# STM32F413 register map
File version: 1.9
CPU: CM4 r0p1, little endian, MPU, FPU, 4 interrupt priority bits
Registers are 32-bit, read-write, reset 0x0 unless marked. A register's access mark holds for its fields unless they carry their own. Offsets are from the block's base; [hi:lo] are bit positions; <NAME> marks a mode.

## PWR — Power control
Base 0x40007000
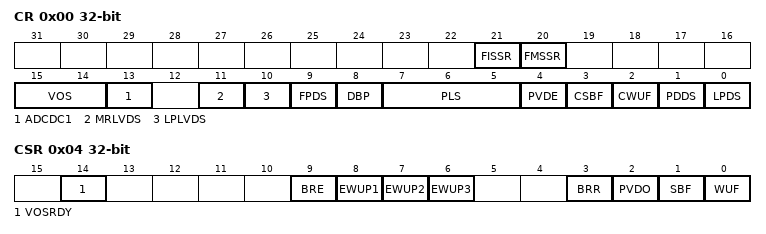
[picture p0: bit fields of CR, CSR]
0x00 CR — power control register
  [21] FISSR — Flash Interface Stop while System Run
    0=Run (Flash Interface clock run (Default value)); 1=Off (Flash Interface clock off)
  [20] FMSSR — Flash Memory Sleep System Run
    0=Standard (Flash standard mode (Default value)); 1=Forced (Flash forced to be in STOP or DeepPower Down mode (depending of FPDS value bit) by hardware)
  [15:14] VOS — Regulator voltage scaling output selection
    1=Scale 3 mode <= 64 MHz; 2=Scale 2 mode (reset value) <= 84 MHz; 3=Scale 1 mode <= 100 MHz
  [13] ADCDC1
  [11] MRLVDS — Main regulator Low Voltage in Deep Sleep
    0=Scale3 (Main regulator in Voltage scale 3 when the device is in Stop mode); 1=LowVoltage (Main regulator in Low Voltage and Flash memory in Deep Sleep mode when the device is in Stop mode)
  [10] LPLVDS — Low-power regulator Low Voltage in Deep Sleep
    0=On (Low-power regulator on if LPDS bit is set when the device is in Stop mode); 1=UnderDrive (Low-power regulator in Low Voltage and Flash memory in Deep Sleep mode if LPDS bit is set when device is in Stop mode)
  [9] FPDS — Flash power down in Stop mode
    0=Idle (Flash memory not in power-down when the device is in Stop mode); 1=PowerDown (Flash memory in power-down when the device is in Stop mode)
  [8] DBP — Disable backup domain write protection
    0=Protected (Access to RTC and RTC Backup registers and backup SRAM disabled); 1=Writable (Access to RTC and RTC Backup registers and backup SRAM enabled)
  [7:5] PLS — PVD level selection
  [4] PVDE — Power voltage detector enable
    0=Disabled (PVD disabled); 1=Enabled (PVD enabled)
  [3] CSBF — Clear standby flag
    on read: 0=Zero (This bit is always read as 0) | on write: 1=Clear the SBF Standby Flag
  [2] CWUF — Clear wakeup flag
    on read: 0=Zero (This bit is always read as 0) | on write: 1=Clear the WUPF Wakeup Flag **after 2 System clock cycles**
  [1] PDDS — Power down deepsleep
    0=Enter Stop mode when the CPU enters deepsleep. The regulator status depends on the LPDS bit; 1=Enter Standby mode when the CPU enters deepsleep
  [0] LPDS — Low-power deep sleep
    0=Main voltage regulator ON during Stop mode; 1=Low-power voltage regulator ON during Stop mode
0x04 CSR access not given — power control/status register
  [14] VOSRDY ro — Regulator voltage scaling output selection ready bit
    0=NotReady; 1=Ready
  [9] BRE rw — Backup regulator enable
    0=Disabled (Backup regulator disabled); 1=Enabled (Backup regulator enabled)
  [8] EWUP1 rw — Enable WKUP1 pin (PA0)
    0=GPIO (WKUP1 pin is used for general purpose I/O. An event on the WKUP1 pin does not wakeup the device from Standby mode); 1=WakeUp (WKUP1 pin is used for wakeup from Standby mode and forced in input pull down configuration (rising edge or falling on WKUP1 pin wakes-up the system from Standby mode))
  [7] EWUP2 — Enable WKUP1 pin (PC0)
    0=GPIO (WKUP2 pin is used for general purpose I/O. An event on the WKUP2 pin does not wakeup the device from Standby mode); 1=WakeUp (WKUP2 pin is used for wakeup from Standby mode and forced in input pull down configuration (rising edge or falling on WKUP2 pin wakes-up the system from Standby mode))
  [6] EWUP3 — Enable WKUP1 pin (PC1)
    0=GPIO (WKUP3 pin is used for general purpose I/O. An event on the WKUP3 pin does not wakeup the device from Standby mode); 1=WakeUp (WKUP3 pin is used for wakeup from Standby mode and forced in input pull down configuration (rising edge or falling on WKUP3 pin wakes-up the system from Standby mode))
  [3] BRR ro — Backup regulator ready
    0=NotReady (Backup Regulator not ready); 1=Ready (Backup Regulator ready)
  [2] PVDO ro — PVD output
    0=Higher (Vdd is higher than the PVD threshold selected with the PLS[2:0] bits); 1=Lower (Vdd is lower than the PVD threshold selected with the PLS[2:0] bits)
  [1] SBF ro — Standby flag
    0=InStandby (Device has not been in Standby mode); 1=NotInStandby (Device has been in Standby mode)
  [0] WUF ro — Wakeup flag
    0=NotOccurred (No wakeup event occurred); 1=Occurred (A wakeup event was received from the WKUP pin or from the RTC alarm (Alarm A or Alarm B), RTC Tamper event, RTC TimeStamp event or RTC Wakeup))
